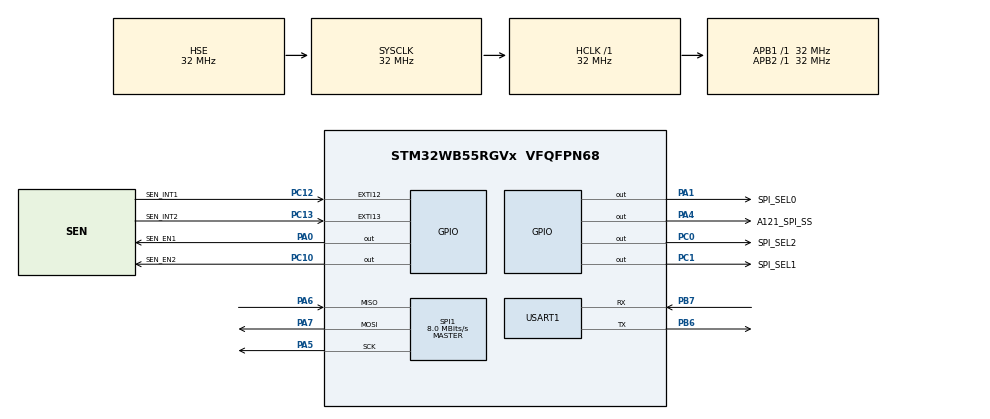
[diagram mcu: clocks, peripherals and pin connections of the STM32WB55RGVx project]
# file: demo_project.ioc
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Mcu.Family=STM32WB
Mcu.Name=STM32WB55RGVx
Mcu.Package=VFQFPN68
NVIC.EXTI15_10_IRQn=true\:0\:0\:false\:false\:true\:true\:true\:true
NVIC.HSEM_IRQn=true\:0\:0\:false\:false\:true\:false\:true\:true
NVIC.IPCC_C1_RX_IRQn=true\:0\:0\:false\:false\:true\:true\:true\:true
NVIC.IPCC_C1_TX_IRQn=true\:0\:0\:false\:false\:true\:true\:true\:true
NVIC.PriorityGroup=NVIC_PRIORITYGROUP_4
NVIC.RTC_WKUP_IRQn=true\:0\:0\:false\:false\:true\:true\:true\:true
OSC_IN.Mode=HSE-External-Oscillator
OSC_IN.Signal=RCC_OSC_IN
OSC_OUT.Mode=HSE-External-Oscillator
OSC_OUT.Signal=RCC_OSC_OUT
PA0.GPIO_Label=SEN_EN1
PA0.GPIO_Speed=GPIO_SPEED_FREQ_VERY_HIGH
PA0.Signal=GPIO_Output
PA1.GPIO_Label=SPI_SEL0
PA1.GPIO_Speed=GPIO_SPEED_FREQ_VERY_HIGH
PA1.Signal=GPIO_Output
PA4.GPIO_Label=A121_SPI_SS
PA4.GPIO_Speed=GPIO_SPEED_FREQ_VERY_HIGH
PA4.PinState=GPIO_PIN_SET
PA4.Signal=GPIO_Output
PA5.Mode=Full_Duplex_Master
PA5.Signal=SPI1_SCK
PA6.Mode=Full_Duplex_Master
PA6.Signal=SPI1_MISO
PA7.Mode=Full_Duplex_Master
PA7.Signal=SPI1_MOSI
PB6.Mode=Asynchronous
PB6.Signal=USART1_TX
PB7.Mode=Asynchronous
PB7.Signal=USART1_RX
PC0.GPIO_Label=SPI_SEL2
PC0.GPIO_Speed=GPIO_SPEED_FREQ_VERY_HIGH
PC0.Signal=GPIO_Output
PC1.GPIO_Label=SPI_SEL1
PC1.GPIO_Speed=GPIO_SPEED_FREQ_VERY_HIGH
PC1.Signal=GPIO_Output
PC10.GPIO_Label=SEN_EN2
PC10.GPIO_Speed=GPIO_SPEED_FREQ_VERY_HIGH
PC10.Signal=GPIO_Output
PC12.GPIO_Label=SEN_INT1
PC12.Signal=GPXTI12
PC13.GPIO_Label=SEN_INT2
PC13.Signal=GPXTI13
PC14-OSC32_IN.Mode=LSE-External-Oscillator
PC14-OSC32_IN.Signal=RCC_OSC32_IN
PC15-OSC32_OUT.Mode=LSE-External-Oscillator
PC15-OSC32_OUT.Signal=RCC_OSC32_OUT
ProjectManager.HeapSize=0x200
ProjectManager.StackSize=0x400
ProjectManager.TargetToolchain=STM32CubeIDE
RCC.ADCFreq_Value=128000000
RCC.AHBFreq_Value=32000000
RCC.APB1Freq_Value=32000000
RCC.APB1TimFreq_Value=32000000
RCC.APB2Freq_Value=32000000
RCC.APB2TimFreq_Value=32000000
RCC.APB3Freq_Value=16000000
RCC.CortexFreq_Value=32000000
RCC.HCLKFreq_Value=32000000
RCC.HSE_VALUE=32000000
RCC.HSI48_VALUE=48000000
RCC.HSI_VALUE=16000000
RCC.MSIClockRange=RCC_MSIRANGE_10
RCC.RFWKPClockSelection=RCC_RFWKPCLKSOURCE_LSE
RCC.RTCClockSelection=RCC_RTCCLKSOURCE_LSE
RCC.SMPSCLockSelection=RCC_SMPSCLKSOURCE_HSE
RCC.SMPSDivider=4
RCC.SYSCLKFreq_VALUE=32000000
RCC.SYSCLKSource=RCC_SYSCLKSOURCE_HSE
RCC.USBFreq_Value=128000000
RCC.VCOOutputFreq_Value=256000000
RF1.Mode=RF1_Activate
RF1.Signal=RF_RF1
SPI1.BaudRatePrescaler=SPI_BAUDRATEPRESCALER_4
SPI1.CalculateBaudRate=8.0 MBits/s
SPI1.DataSize=SPI_DATASIZE_8BIT
SPI1.Direction=SPI_DIRECTION_2LINES
SPI1.Mode=SPI_MODE_MASTER
SPI1.VirtualType=VM_MASTER
STM32_WPAN.AD_TYPE_COMPLETE_LOCAL_NAME=MonashMap
STM32_WPAN.AD_TYPE_COMPLETE_LOCAL_NAME_LENGTH=10
STM32_WPAN.CFG_LSCLK_LSE=0
STM32_WPAN.CUSTOM_P2P_SERVER=Disabled
STM32_WPAN.CUSTOM_TEMPLATE=Enabled
STM32_WPAN.INCLUDE_AD_TYPE_COMPLETE_LOCAL_NAME=1
STM32_WPAN.NUMBER_OF_SERVICES=1
STM32_WPAN.SERVICE1_CHAR1_LONG_NAME=myCharNotify
STM32_WPAN.SERVICE1_CHAR1_PROP_NOTIFY=CHAR_PROP_NOTIFY
STM32_WPAN.SERVICE1_CHAR1_SHORT_NAME=myCharNotify
STM32_WPAN.SERVICE1_CHAR1_VALUE_LENGTH=512
STM32_WPAN.SERVICE1_LONG_NAME=mySVC
STM32_WPAN.SERVICE1_SHORT_NAME=mySVC
STM32_WPAN.SERVICE1_UUID=00 01
USART1.VirtualMode-Asynchronous=VM_ASYNC
VP_HSEM_VS_HSEM.Mode=HSEM_Activate
VP_IPCC_VS_IPCC.Mode=IPCC_Activate
VP_MEMORYMAP_VS_MEMORYMAP.Mode=CurAppReg
VP_RTC_VS_RTC_Activate.Mode=RTC_Enabled
VP_RTC_VS_RTC_WakeUp_intern.Mode=WakeUp
VP_SEQUENCER_VS_SEQUENCER.Mode=SEQUENCER_Enabled
VP_STM32_WPAN_VS_BLE_HOST.Mode=STM32_WPAN_Enabled
VP_TINY_LPM_VS_TINY_LPM.Mode=TINY_LPM_Enabled
board=custom

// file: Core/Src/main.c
/* USER CODE BEGIN Header */
/**
  ******************************************************************************
  * @file           : main.c
  * @brief          : Main program body
  ******************************************************************************
  * @attention
  *
  * Copyright (c) 2024 STMicroelectronics.
  * All rights reserved.
  *
  * This software is licensed under terms that can be found in the LICENSE file
  * in the root directory of this software component.
  * If no LICENSE file comes with this software, it is provided AS-IS.
  *
  ******************************************************************************
  */
/* USER CODE END Header */
#include "main.h"
#include "ipcc.h"
#include "memorymap.h"
#include "rf.h"
#include "rtc.h"
#include "spi.h"
#include "usart.h"
#include "gpio.h"

/* USER CODE BEGIN Includes */
#include <stdio.h>
/* USER CODE END Includes */

void SystemClock_Config(void);
void PeriphCommonClock_Config(void);

/* USER CODE BEGIN 0 */
int _write(int file, char *ptr, int len)
{
    (void)file;
    HAL_UART_Transmit(&huart1, (uint8_t*)ptr, len, 0xFFFF);
    return len;
}
/* USER CODE END 0 */

int main(void)
{

  /* MCU Configuration--------------------------------------------------------*/

  /* Reset of all peripherals, Initializes the Flash interface and the Systick. */
  HAL_Init();
  /* Config code for STM32_WPAN (HSE Tuning must be done before system clock configuration) */
  MX_APPE_Config();

  /* Configure the system clock */
  SystemClock_Config();

  /* Configure the peripherals common clocks */
  PeriphCommonClock_Config();

  /* IPCC initialisation */
  MX_IPCC_Init();

  /* Initialize all configured peripherals */
  MX_GPIO_Init();
  MX_RTC_Init();
  MX_USART1_UART_Init();
  MX_SPI1_Init();
  MX_RF_Init();

  /* Init code for STM32_WPAN */
  MX_APPE_Init();

  /* Infinite loop */
  while (1)
  {
    MX_APPE_Process();

  }
}

void SystemClock_Config(void)
{
  RCC_OscInitTypeDef RCC_OscInitStruct = {0};
  RCC_ClkInitTypeDef RCC_ClkInitStruct = {0};

  /** Configure LSE Drive Capability
  */
  HAL_PWR_EnableBkUpAccess();
  __HAL_RCC_LSEDRIVE_CONFIG(RCC_LSEDRIVE_MEDIUMHIGH);

  /** Configure the main internal regulator output voltage
  */
  __HAL_PWR_VOLTAGESCALING_CONFIG(PWR_REGULATOR_VOLTAGE_SCALE1);

  /** Initializes the RCC Oscillators according to the specified parameters
  * in the RCC_OscInitTypeDef structure.
  */
  RCC_OscInitStruct.OscillatorType = RCC_OSCILLATORTYPE_HSI|RCC_OSCILLATORTYPE_HSE
                              |RCC_OSCILLATORTYPE_LSE;
  RCC_OscInitStruct.HSEState = RCC_HSE_ON;
  RCC_OscInitStruct.LSEState = RCC_LSE_ON;
  RCC_OscInitStruct.HSIState = RCC_HSI_ON;
  RCC_OscInitStruct.HSICalibrationValue = RCC_HSICALIBRATION_DEFAULT;
  RCC_OscInitStruct.PLL.PLLState = RCC_PLL_NONE;
  if (HAL_RCC_OscConfig(&RCC_OscInitStruct) != HAL_OK)
  {
    Error_Handler();
  }

  /** Configure the SYSCLKSource, HCLK, PCLK1 and PCLK2 clocks dividers
  */
  RCC_ClkInitStruct.ClockType = RCC_CLOCKTYPE_HCLK4|RCC_CLOCKTYPE_HCLK2
                              |RCC_CLOCKTYPE_HCLK|RCC_CLOCKTYPE_SYSCLK
                              |RCC_CLOCKTYPE_PCLK1|RCC_CLOCKTYPE_PCLK2;
  RCC_ClkInitStruct.SYSCLKSource = RCC_SYSCLKSOURCE_HSE;
  RCC_ClkInitStruct.AHBCLKDivider = RCC_SYSCLK_DIV1;
  RCC_ClkInitStruct.APB1CLKDivider = RCC_HCLK_DIV1;
  RCC_ClkInitStruct.APB2CLKDivider = RCC_HCLK_DIV1;
  RCC_ClkInitStruct.AHBCLK2Divider = RCC_SYSCLK_DIV1;
  RCC_ClkInitStruct.AHBCLK4Divider = RCC_SYSCLK_DIV1;

  if (HAL_RCC_ClockConfig(&RCC_ClkInitStruct, FLASH_LATENCY_1) != HAL_OK)
  {
    Error_Handler();
  }
}

void PeriphCommonClock_Config(void)
{
  RCC_PeriphCLKInitTypeDef PeriphClkInitStruct = {0};

  /** Initializes the peripherals clock
  */
  PeriphClkInitStruct.PeriphClockSelection = RCC_PERIPHCLK_SMPS|RCC_PERIPHCLK_RFWAKEUP;
  PeriphClkInitStruct.RFWakeUpClockSelection = RCC_RFWKPCLKSOURCE_LSE;
  PeriphClkInitStruct.SmpsClockSelection = RCC_SMPSCLKSOURCE_HSE;
  PeriphClkInitStruct.SmpsDivSelection = RCC_SMPSCLKDIV_RANGE1;

  if (HAL_RCCEx_PeriphCLKConfig(&PeriphClkInitStruct) != HAL_OK)
  {
    Error_Handler();
  }
}

void Error_Handler(void)
{
  __disable_irq();
  while (1)
  {
  }
}
